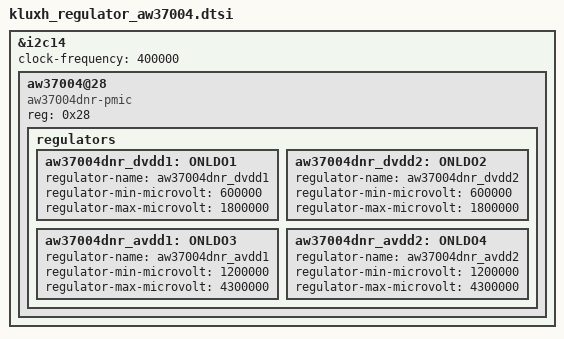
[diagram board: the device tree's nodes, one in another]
/* SPDX-License-Identifier: GPL-2.0
 *
 * Copyright (C) 2021 MediaTek Inc.
 */

/* aw37004 */

&i2c14 {
	clock-frequency = <400000>;
	aw37004@28 {
		compatible = "aw37004dnr-pmic";
		reg = <0x28>;

		regulators {
			aw37004dnr_dvdd1:ONLDO1 {
				regulator-name = "aw37004dnr_dvdd1";
				regulator-min-microvolt = <600000>;
				regulator-max-microvolt = <1800000>;
			};
			aw37004dnr_dvdd2:ONLDO2 {
				regulator-name = "aw37004dnr_dvdd2";
				regulator-min-microvolt = <600000>;
				regulator-max-microvolt = <1800000>;
			};
			aw37004dnr_avdd1:ONLDO3 {
				regulator-name = "aw37004dnr_avdd1";
				regulator-min-microvolt = <1200000>;
				regulator-max-microvolt = <4300000>;
			};
			aw37004dnr_avdd2:ONLDO4 {
				regulator-name = "aw37004dnr_avdd2";
				regulator-min-microvolt = <1200000>;
				regulator-max-microvolt = <4300000>;
			};
		};
	};
};
